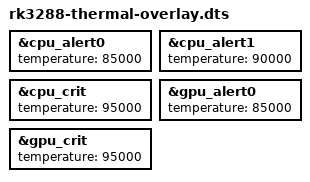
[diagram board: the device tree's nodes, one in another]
/dts-v1/;
/plugin/;

&cpu_alert0 {
  temperature = <85000>;
};
&cpu_alert1 {
  temperature = <90000>;
};
&cpu_crit {
  temperature = <95000>;
};
&gpu_alert0 {
  temperature = <85000>;
};
&gpu_crit {
  temperature = <95000>;
};
